# nrf52 register map
Vendor: Nordic Semiconductor; Series: nrf52; File version: 1
CPU: CM4 r0p1, little endian, MPU, FPU, 3 interrupt priority bits
Registers are 32-bit, read-write, reset 0x0 unless marked. A register's access mark holds for its fields unless they carry their own. Offsets are from the block's base; [hi:lo] are bit positions; {n}, {i} and the like mark numbered series; 'fields as' and 'values as' point back to an identical list.

## RTC0 — Real time counter 0
Base 0x4000B000
Same registers: RTC1 0x40011000, RTC2 0x40024000
0x00 TASKS_START wo — Start RTC COUNTER
0x04 TASKS_STOP wo — Stop RTC COUNTER
0x08 TASKS_CLEAR wo — Clear RTC COUNTER
0x0C TASKS_TRIGOVRFLW wo — Set COUNTER to 0xFFFFF0
0x100 EVENTS_TICK — Event on COUNTER increment
0x104 EVENTS_OVRFLW — Event on COUNTER overflow
{0x140+4i} EVENTS_COMPARE[{i}] (i=0..3) — Description collection[0]: Compare event on CC[0] match
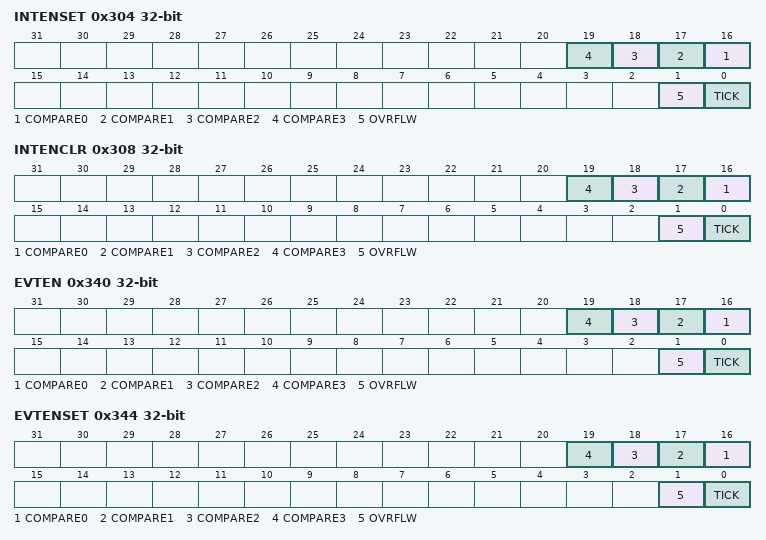
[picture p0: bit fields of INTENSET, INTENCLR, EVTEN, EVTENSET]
0x304 INTENSET — Enable interrupt
  [all] fields
    on read: 0=Disabled (Read: Disabled); 1=Enabled (Read: Enabled) | on write: 1=Set (Enable)
  [n+16] COMPARE{n} (n=0..3) — Write '1' to Enable interrupt for COMPARE[{n}] event
  [1] OVRFLW — Write '1' to Enable interrupt for OVRFLW event
  [0] TICK — Write '1' to Enable interrupt for TICK event
0x308 INTENCLR — Disable interrupt
  [all] fields
    on read: 0=Disabled (Read: Disabled); 1=Enabled (Read: Enabled) | on write: 1=Clear (Disable)
  [n+16] COMPARE{n} (n=0..3) — Write '1' to Disable interrupt for COMPARE[{n}] event
  [1] OVRFLW — Write '1' to Disable interrupt for OVRFLW event
  [0] TICK — Write '1' to Disable interrupt for TICK event
0x340 EVTEN — Enable or disable event routing
  [all] fields
    0=Disabled; 1=Enabled
  [n+16] COMPARE{n} (n=0..3) — Enable or disable event routing for COMPARE[{n}] event
  [1] OVRFLW — Enable or disable event routing for OVRFLW event
  [0] TICK — Enable or disable event routing for TICK event
0x344 EVTENSET — Enable event routing
  [all] fields
    values as the fields of INTENSET
  [n+16] COMPARE{n} (n=0..3) — Write '1' to Enable event routing for COMPARE[{n}] event
  [1] OVRFLW — Write '1' to Enable event routing for OVRFLW event
  [0] TICK — Write '1' to Enable event routing for TICK event
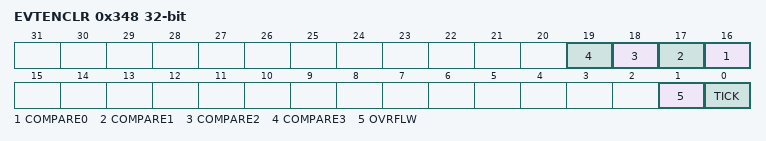
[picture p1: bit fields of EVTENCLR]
0x348 EVTENCLR — Disable event routing
  [all] fields
    values as the fields of INTENCLR
  [n+16] COMPARE{n} (n=0..3) — Write '1' to Disable event routing for COMPARE[{n}] event
  [1] OVRFLW — Write '1' to Disable event routing for OVRFLW event
  [0] TICK — Write '1' to Disable event routing for TICK event
0x504 COUNTER ro — Current COUNTER value
  [23:0] COUNTER — Counter value
0x508 PRESCALER — 12 bit prescaler for COUNTER frequency (32768/(PRESCALER+1)).Must be written when RTC is stopped
  [11:0] PRESCALER — Prescaler value
{0x540+4i} CC[{i}] (i=0..3) — Description collection[0]: Compare register 0
  [23:0] COMPARE — Compare value

## TEMP — Temperature Sensor
Base 0x4000C000
0x00 TASKS_START wo — Start temperature measurement
0x04 TASKS_STOP wo — Stop temperature measurement
0x100 EVENTS_DATARDY — Temperature measurement complete, data ready
0x304 INTENSET — Enable interrupt
  [0] DATARDY — Write '1' to Enable interrupt for DATARDY event
    on read: 0=Disabled (Read: Disabled); 1=Enabled (Read: Enabled) | on write: 1=Set (Enable)
0x308 INTENCLR — Disable interrupt
  [0] DATARDY — Write '1' to Disable interrupt for DATARDY event
    on read: 0=Disabled (Read: Disabled); 1=Enabled (Read: Enabled) | on write: 1=Clear (Disable)
0x508 TEMP ro — Temperature in degC (0.25deg steps)
0x520 A0 reset 0x320 — Slope of 1st piece wise linear function
  [11:0] A0
0x524 A1 reset 0x343 — Slope of 2nd piece wise linear function
  [11:0] A1
0x528 A2 reset 0x35D — Slope of 3rd piece wise linear function
  [11:0] A2
0x52C A3 reset 0x400 — Slope of 4th piece wise linear function
  [11:0] A3
0x530 A4 reset 0x47F — Slope of 5th piece wise linear function
  [11:0] A4
0x534 A5 reset 0x37B — Slope of 6th piece wise linear function
  [11:0] A5
0x540 B0 reset 0x3FCC — y-intercept of 1st piece wise linear function
  [13:0] B0
0x544 B1 reset 0x3F98 — y-intercept of 2nd piece wise linear function
  [13:0] B1
0x548 B2 reset 0x3F98 — y-intercept of 3rd piece wise linear function
  [13:0] B2
0x54C B3 reset 0x12 — y-intercept of 4th piece wise linear function
  [13:0] B3
0x550 B4 reset 0x6A — y-intercept of 5th piece wise linear function
  [13:0] B4
0x554 B5 reset 0x3DD0 — y-intercept of 6th piece wise linear function
  [13:0] B5
0x560 T0 reset 0xE2 — End point of 1st piece wise linear function
  [7:0] T0
0x564 T1 — End point of 2nd piece wise linear function
  [7:0] T1
0x568 T2 reset 0x14 — End point of 3rd piece wise linear function
  [7:0] T2
0x56C T3 reset 0x19 — End point of 4th piece wise linear function
  [7:0] T3
0x570 T4 reset 0x50 — End point of 5th piece wise linear function
  [7:0] T4

## Notices in the file
Copyright (c) 2010 - 2018, Nordic Semiconductor ASA
All rights reserved.
Redistribution and use in source and binary forms, with or without modification,
are permitted provided that the following conditions are met:
1. Redistributions of source code must retain the above copyright notice, this
list of conditions and the following disclaimer.
2. Redistributions in binary form, except as embedded into a Nordic
Semiconductor ASA integrated circuit in a product or a software update for
such product, must reproduce the above copyright notice, this list of
conditions and the following disclaimer in the documentation and/or other
materials provided with the distribution.
3. Neither the name of Nordic Semiconductor ASA nor the names of its
contributors may be used to endorse or promote products derived from this
software without specific prior written permission.
4. This software, with or without modification, must only be used with a
Nordic Semiconductor ASA integrated circuit.
5. Any software provided in binary form under this license must not be reverse
engineered, decompiled, modified and/or disassembled.
THIS SOFTWARE IS PROVIDED BY NORDIC SEMICONDUCTOR ASA "AS IS" AND ANY EXPRESS
OR IMPLIED WARRANTIES, INCLUDING, BUT NOT LIMITED TO, THE IMPLIED WARRANTIES
OF MERCHANTABILITY, NONINFRINGEMENT, AND FITNESS FOR A PARTICULAR PURPOSE ARE
DISCLAIMED. IN NO EVENT SHALL NORDIC SEMICONDUCTOR ASA OR CONTRIBUTORS BE
LIABLE FOR ANY DIRECT, INDIRECT, INCIDENTAL, SPECIAL, EXEMPLARY, OR
CONSEQUENTIAL DAMAGES (INCLUDING, BUT NOT LIMITED TO, PROCUREMENT OF SUBSTITUTE
GOODS OR SERVICES; LOSS OF USE, DATA, OR PROFITS; OR BUSINESS INTERRUPTION)
HOWEVER CAUSED AND ON ANY THEORY OF LIABILITY, WHETHER IN CONTRACT, STRICT
LIABILITY, OR TORT (INCLUDING NEGLIGENCE OR OTHERWISE) ARISING IN ANY WAY OUT
OF THE USE OF THIS SOFTWARE, EVEN IF ADVISED OF THE POSSIBILITY OF SUCH DAMAGE.
